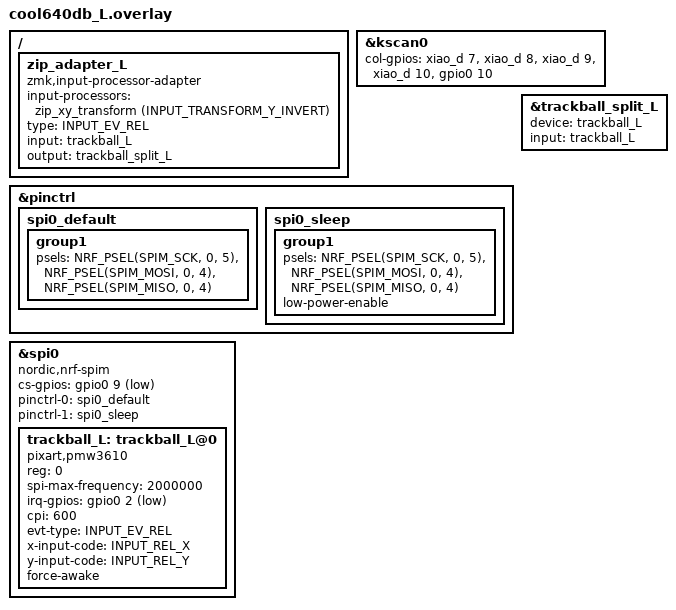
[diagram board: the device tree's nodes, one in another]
#include <zephyr/dt-bindings/input/input-event-codes.h>
#include "cool640db.dtsi"

&kscan0 {
    col-gpios = <&xiao_d 7 GPIO_ACTIVE_HIGH>,
                <&xiao_d 8 GPIO_ACTIVE_HIGH>,
                <&xiao_d 9 GPIO_ACTIVE_HIGH>,
                <&xiao_d 10 GPIO_ACTIVE_HIGH>,
                <&gpio0 10 GPIO_ACTIVE_HIGH>;
};

&pinctrl {
    spi0_default: spi0_default {
        group1 {
            psels = <NRF_PSEL(SPIM_SCK, 0, 5)>,
                    <NRF_PSEL(SPIM_MOSI, 0, 4)>,
                    <NRF_PSEL(SPIM_MISO, 0, 4)>;
        };
    };

    spi0_sleep: spi0_sleep {
        group1 {
            psels = <NRF_PSEL(SPIM_SCK, 0, 5)>,
                    <NRF_PSEL(SPIM_MOSI, 0, 4)>,
                    <NRF_PSEL(SPIM_MISO, 0, 4)>;
            low-power-enable;
        };
    };
};

&spi0 {
    status = "okay";
    cs-gpios = <&gpio0 9 GPIO_ACTIVE_LOW>;
    pinctrl-0 = <&spi0_default>;
    pinctrl-1 = <&spi0_sleep>;
    pinctrl-names = "default", "sleep";
    compatible = "nordic,nrf-spim";

    trackball_L: trackball_L@0 {
        status = "okay";
        compatible = "pixart,pmw3610";
        reg = <0>;
        spi-max-frequency = <2000000>;
        irq-gpios = <&gpio0 2 (GPIO_ACTIVE_LOW | GPIO_PULL_UP)>;
        cpi = <600>;
        evt-type = <INPUT_EV_REL>;
        x-input-code = <INPUT_REL_X>;
        y-input-code = <INPUT_REL_Y>;
        force-awake;
    };
};

// 左側のトラックボールの入力をスプリット経由で送信するための正しい定義
/ {
    zip_adapter_L {
        compatible = "zmk,input-processor-adapter";
        #input-processor-cells = <0>;
        input-processors = <&zip_xy_transform (INPUT_TRANSFORM_Y_INVERT)>;
        type = <INPUT_EV_REL>;
        input = <&trackball_L>;
        output = <&trackball_split_L>;
    };
};

&trackball_split_L {
    status = "okay";
    device = <&trackball_L>;
    input = <&trackball_L>;
};
